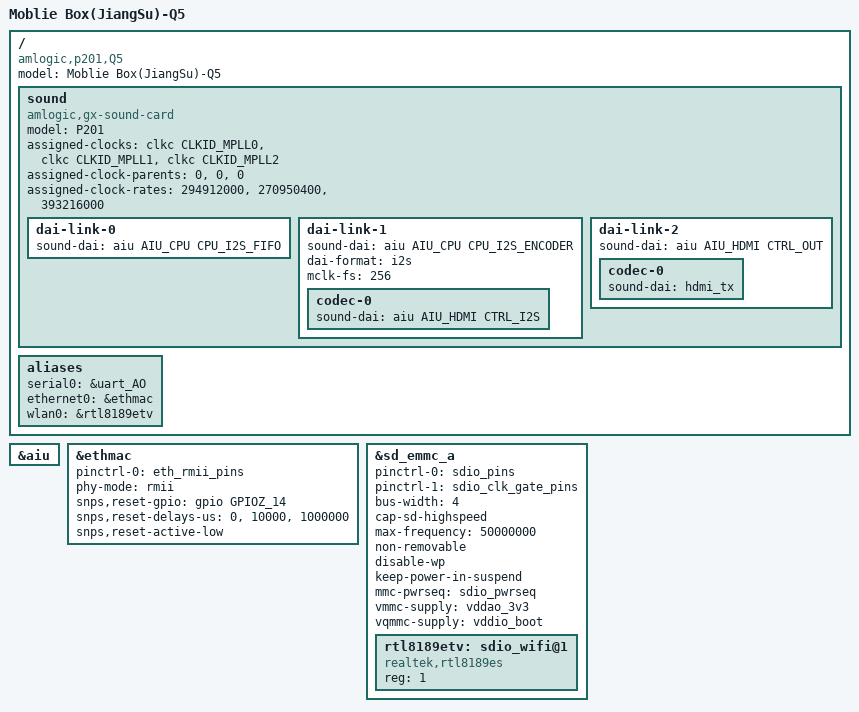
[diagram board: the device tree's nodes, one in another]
// SPDX-License-Identifier: (GPL-2.0+ OR MIT)
/*
 * Copyright (c) 2016 Andreas Färber
 * Copyright (c) 2016 BayLibre, Inc.
 * Author: Kevin Hilman <khilman@kernel.org>
 */

/dts-v1/;

#include "meson-gxbb-p20x.dtsi"

/ {
	compatible = "amlogic,p201,Q5", "amlogic,meson-gxbb", "amlogic,meson-gxbb-Q5";
	model = "Moblie Box(JiangSu)-Q5";

	sound {
		compatible = "amlogic,gx-sound-card";
		model = "P201";
		assigned-clocks = <&clkc CLKID_MPLL0>,
				  <&clkc CLKID_MPLL1>,
				  <&clkc CLKID_MPLL2>;
		assigned-clock-parents = <0>, <0>, <0>;
		assigned-clock-rates = <294912000>,
				       <270950400>,
				       <393216000>;

		dai-link-0 {
			sound-dai = <&aiu AIU_CPU CPU_I2S_FIFO>;
		};

		dai-link-1 {
			sound-dai = <&aiu AIU_CPU CPU_I2S_ENCODER>;
			dai-format = "i2s";
			mclk-fs = <256>;

			codec-0 {
				sound-dai = <&aiu AIU_HDMI CTRL_I2S>;
			};
		};

		dai-link-2 {
			sound-dai = <&aiu AIU_HDMI CTRL_OUT>;

			codec-0 {
				sound-dai = <&hdmi_tx>;
			};
		};
	};

	aliases {
		serial0 = &uart_AO;
		ethernet0 = &ethmac;
		wlan0 = &rtl8189etv;
	};

};
&aiu {
	status = "okay";
};

&ethmac {
	status = "okay";
	pinctrl-0 = <&eth_rmii_pins>;
	pinctrl-names = "default";
	phy-mode = "rmii";

	snps,reset-gpio = <&gpio GPIOZ_14 0>;
	snps,reset-delays-us = <0>, <10000>, <1000000>;
	snps,reset-active-low;
};

/* Wireless SDIO Module */
&sd_emmc_a {
	status = "okay";
	pinctrl-0 = <&sdio_pins>;
	pinctrl-1 = <&sdio_clk_gate_pins>;
	pinctrl-names = "default", "clk-gate";
	#address-cells = <1>;
	#size-cells = <0>;

	bus-width = <4>;
	cap-sd-highspeed;
	max-frequency = <50000000>;

	non-removable;
	disable-wp;

	/* WiFi firmware requires power to be kept while in suspend */
	keep-power-in-suspend;

	mmc-pwrseq = <&sdio_pwrseq>;

	vmmc-supply = <&vddao_3v3>;
	vqmmc-supply = <&vddio_boot>;

	rtl8189etv: sdio_wifi@1 {
		reg = <1>;
		compatible = "realtek,rtl8189es";
	};
};
